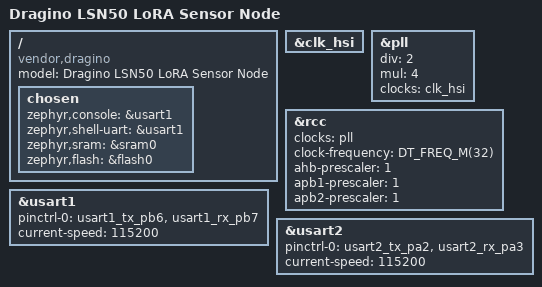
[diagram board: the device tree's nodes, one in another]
/*
 * Copyright (c) 2018 Endre Karlson <endre.karlson@gmail.com>
 *
 * SPDX-License-Identifier: Apache-2.0
 */

/dts-v1/;
#include <st/l0/stm32l072Xz.dtsi>
#include <st/l0/stm32l072c(b-z)tx-pinctrl.dtsi>

/ {
	model = "Dragino LSN50 LoRA Sensor Node";
	compatible = "vendor,dragino";

	chosen {
		zephyr,console = &usart1;
		zephyr,shell-uart = &usart1;
		zephyr,sram = &sram0;
		zephyr,flash = &flash0;
	};
};

&clk_hsi {
	status = "okay";
};

&pll {
	div = <2>;
	mul = <4>;
	clocks = <&clk_hsi>;
	status = "okay";
};

&rcc {
	clocks = <&pll>;
	clock-frequency = <DT_FREQ_M(32)>;
	ahb-prescaler = <1>;
	apb1-prescaler = <1>;
	apb2-prescaler = <1>;
};

&usart1 {
	pinctrl-0 = <&usart1_tx_pb6 &usart1_rx_pb7>;
	pinctrl-names = "default";
	current-speed = <115200>;
	status = "okay";
};

&usart2 {
	pinctrl-0 = <&usart2_tx_pa2 &usart2_rx_pa3>;
	pinctrl-names = "default";
	current-speed = <115200>;
	status = "okay";
};
